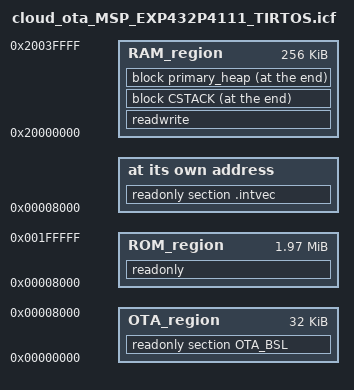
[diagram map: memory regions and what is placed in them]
define exported symbol __intvec_start__ = 0x00008000;

/*-Memory Regions-*/
define symbol ROM_start__   = 0x00008000;
define symbol ROM_end__     = 0x001FFFFF;
define symbol RAM_start__   = 0x20000000;
define symbol RAM_end__     = 0x2003FFFF;

define memory mem with size = 4G;
define region ROM_region   = mem:[from ROM_start__   to ROM_end__];
define region RAM_region   = mem:[from RAM_start__   to RAM_end__];


define symbol STACKSIZE = 1024;
define block CSTACK with alignment = 8, size = STACKSIZE  { section .stack };
do not initialize { section .stack };
do not initialize  { section .noinit };

place in RAM_region   { readwrite };
initialize by copy { readwrite };

place at address mem:__intvec_start__ { readonly section .intvec };
place in ROM_region   { readonly };

place at end of RAM_region  { block CSTACK };

/* HeapMem Primary Heap configuration */
define symbol HEAPSIZE = 0x8000;
define block primary_heap with size = HEAPSIZE {};

/* place heap just before CSTACK */
place at end of RAM_region { block primary_heap };

/* Section for OTA bootloader */
define region OTA_region = mem:[ from 0x0000 to 0x8000 ];
place in OTA_region { readonly section OTA_BSL };

/* define buffer start and end symbols for HeapMem Primary Heap */
define exported symbol __primary_heap_end__ = end(RAM_region) - STACKSIZE;
define exported symbol __primary_heap_start__ = __primary_heap_end__ - HEAPSIZE;
